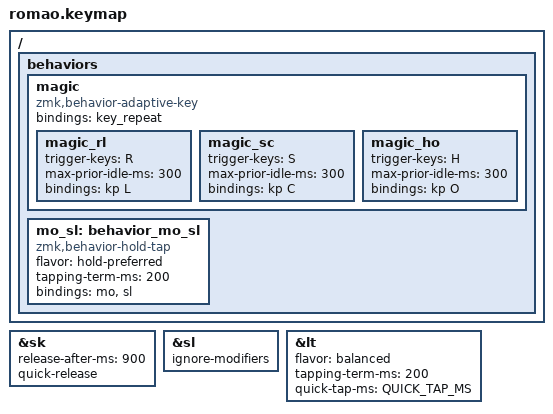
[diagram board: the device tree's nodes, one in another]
#include <behaviors.dtsi>
#include <behaviors/num_word.dtsi> // Requires auto-layer module.
#include <dt-bindings/zmk/keys.h>
// #ifdef CONFIG_WIRELESS
  #include <dt-bindings/zmk/bt.h>
  #include <dt-bindings/zmk/outputs.h>
  #define _BT_SEL_KEYS_                                                        \
      &bt BT_SEL 0 &bt BT_SEL 1 &bt BT_SEL 2 &bt BT_SEL 3 &bt BT_CLR
// #else
//   #define _BT_SEL_KEYS_ &trans &trans &trans &trans &trans
// #endif

#include "zmk-helpers/helper.h"
// #include "zmk-helpers/unicode-chars/greek.dtsi"
// #include "zmk-helpers/unicode-chars/german.dtsi"

#define DEF 0
#define DEF2 1
#define NAV 2
#define SYM 3
#define FN 4
#define NUM 5
#define SYS 6 
#define MOUSE 7
#define DEFs DEF DEF2

#define XXX &none
#define ___ &trans

/* Global defaults */

#define QUICK_TAP_MS 175

&sk {
  release-after-ms = <900>;
  quick-release;
};

&sl { // Allow sticky mods to chord across sticky layers.
  ignore-modifiers;
};

&lt {
  flavor = "balanced";
  tapping-term-ms = <200>;
  quick-tap-ms = <QUICK_TAP_MS>;
};

#ifndef ZMK_BASE_LAYER
  #define ZMK_BASE_LAYER(name, LT, RT, LM, RM, LB, RB, LH, RH)                 \
      ZMK_LAYER(name, LT RT LM RM LB RB LH RH)
#endif

/ {
    behaviors {
        magic: magic {
            compatible = "zmk,behavior-adaptive-key";
            #binding-cells = <0>;
            bindings = <&key_repeat>;

            magic_rl { trigger-keys = <R>; max-prior-idle-ms = <300>; bindings = <&kp L>; };
			magic_sc { trigger-keys = <S>; max-prior-idle-ms = <300>; bindings = <&kp C>; };
			magic_ho { trigger-keys = <H>; max-prior-idle-ms = <300>; bindings = <&kp O>; };
			// magic_my { trigger-keys = <M>; max-prior-idle-ms = <300>; bindings = <&kp Y>;
			// magic_ay { trigger-keys = <A>; max-prior-idle-ms = <300>; bindings = <&kp Y>;
		};

		mo_sl: behavior_mo_sl {
            compatible = "zmk,behavior-hold-tap";
            #binding-cells = <2>;
            flavor = "hold-preferred";
            tapping-term-ms = <200>;
            bindings = <&mo>, <&sl>;
        };
    };
};

//   b ø m k g   l x o ⌫ u
//   d n q s w t   r z a y e i
//   f num c v p   h|v j , ; .
//         ⌫  
ZMK_BASE_LAYER(Base,
//╭─────────────┬─────────────┬─────────────┬─────────────┬─────────────╮ ╭─────────────┬─────────────┬─────────────┬─────────────┬─────────────╮
    ___           &kp B         &kp M         &kp G         ___         ,   ___           &kp L         &kp O         &kp U         ___         ,
//├─────────────┼─────────────┼─────────────┼─────────────┼─────────────┤ ├─────────────┼─────────────┼─────────────┼─────────────┼─────────────┤
    &kp D         &kp N         &kp S         &kp T         ___         ,   ___           &kp R         &kp A         &kp E         &kp I       ,
//├─────────────┼─────────────┼─────────────┼─────────────┼─────────────┤ ├─────────────┼─────────────┼─────────────┼─────────────┼─────────────┤
    ___           &kp F         &kp C         &kp P         ___         ,   ___           &kp H         &magic        &kp DOT       ___         ,

//╰─────────────┼─────────────┴─────────────┼─────────────┼─────────────┤ ├─────────────┼─────────────┼─────────────┴───────────────────────────╯
                                              &kp BSPC      &sl DEF2     ,   &kp SPACE     &kp TAB
//                                          ╰─────────────┴─────────────╯ ╰─────────────┴─────────────╯
)

ZMK_BASE_LAYER(DEF2,
//╭─────────────┬─────────────┬─────────────┬─────────────┬─────────────╮ ╭─────────────┬─────────────┬─────────────┬─────────────┬─────────────╮
    ___           &kp Q         ___           &kp K         ___         ,   ___           &kp L         &kp O         &kp U         ___         ,
//├─────────────┼─────────────┼─────────────┼─────────────┼─────────────┤ ├─────────────┼─────────────┼─────────────┼─────────────┼─────────────┤
    &kp Y         &kp Z         &kp X         &kp W         ___         ,   ___           &kp R         &kp A         &kp E         &kp I       ,
//├─────────────┼─────────────┼─────────────┼─────────────┼─────────────┤ ├─────────────┼─────────────┼─────────────┼─────────────┼─────────────┤
    ___           &kp J         ___           &kp V         ___         ,   ___           &kp H         &kp COMMA     &kp DOT       ___         ,

//╰─────────────┼─────────────┴─────────────┼─────────────┼─────────────┤ ├─────────────┼─────────────┼─────────────┴───────────────────────────╯
                                               &kp BSPC           &sl DEF2,   &kp SPACE    &kp TAB
//                                          ╰─────────────┴─────────────╯ ╰─────────────┴─────────────╯
)


/* vim: set ft=c tw=146: */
